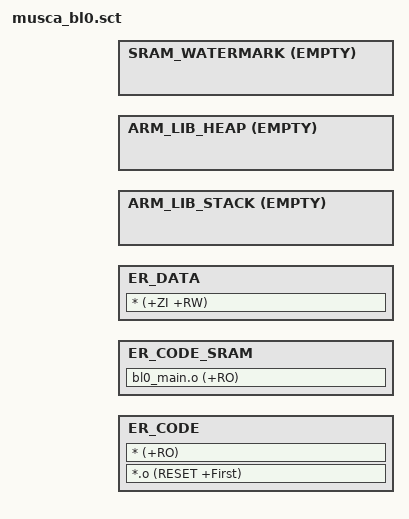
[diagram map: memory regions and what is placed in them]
;/*
; * Copyright (c) 2018-2019 Arm Limited
; *
; * Licensed under the Apache License, Version 2.0 (the "License");
; * you may not use this file except in compliance with the License.
; * You may obtain a copy of the License at
; *
; *     http://www.apache.org/licenses/LICENSE-2.0
; *
; * Unless required by applicable law or agreed to in writing, software
; * distributed under the License is distributed on an "AS IS" BASIS,
; * WITHOUT WARRANTIES OR CONDITIONS OF ANY KIND, either express or implied.
; * See the License for the specific language governing permissions and
; * limitations under the License.
; *
; */

#include "region_defs_bl0.h"

LR_CODE BL0_FLASH_BASE {
    ER_CODE BL0_FLASH_BASE BL0_FLASH_SIZE {
        *.o (RESET +First)
        * (+RO)
    }

    ER_CODE_SRAM BL0_CODE_SRAM_BASE BL0_CODE_SRAM_SIZE {
        bl0_main.o (+RO)
    }

    ER_DATA BL0_DATA_BASE BL0_DATA_SIZE {
        * (+ZI +RW)
    }

    /* MSP */
    ARM_LIB_STACK +0 ALIGN 32 EMPTY BL0_MSP_STACK_SIZE {
    }

    ARM_LIB_HEAP +0 ALIGN 8 EMPTY BL0_HEAP_SIZE {
    }

    /* This empty, zero long execution region is here to mark the limit address
     * of the last execution region that is allocated in SRAM.
     */
    SRAM_WATERMARK +0 EMPTY 0x0 {
    }

    /* Make sure that the sections allocated in the SRAM does not exceed the
     * size of the SRAM available.
     */
    ScatterAssert(ImageLimit(SRAM_WATERMARK) <= BL0_DATA_BASE + BL0_DATA_SIZE)
}

